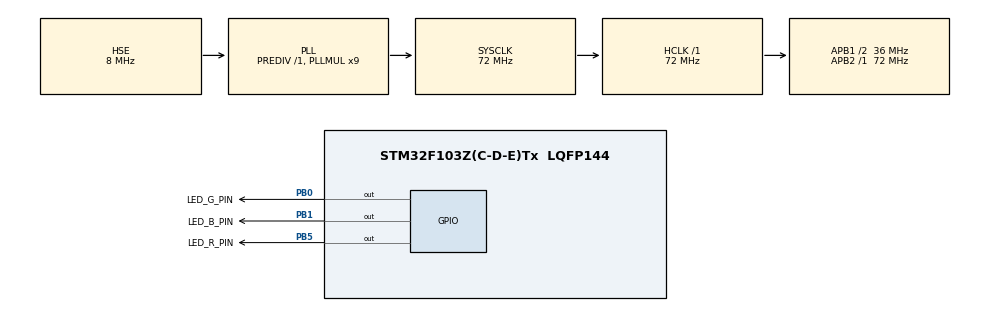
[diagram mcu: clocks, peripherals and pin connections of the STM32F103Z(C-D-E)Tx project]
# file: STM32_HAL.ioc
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Mcu.Family=STM32F1
Mcu.Name=STM32F103Z(C-D-E)Tx
Mcu.Package=LQFP144
NVIC.PriorityGroup=NVIC_PRIORITYGROUP_4
OSC_IN.Mode=HSE-External-Oscillator
OSC_IN.Signal=RCC_OSC_IN
OSC_OUT.Mode=HSE-External-Oscillator
OSC_OUT.Signal=RCC_OSC_OUT
PA13.Mode=JTAG_5_pins
PA13.Signal=SYS_JTMS-SWDIO
PA14.Mode=JTAG_5_pins
PA14.Signal=SYS_JTCK-SWCLK
PA15.Mode=JTAG_5_pins
PA15.Signal=SYS_JTDI
PB0.GPIO_Label=LED_G_PIN
PB0.GPIO_Speed=GPIO_SPEED_FREQ_HIGH
PB0.PinState=GPIO_PIN_SET
PB0.Signal=GPIO_Output
PB1.GPIO_Label=LED_B_PIN
PB1.GPIO_Speed=GPIO_SPEED_FREQ_HIGH
PB1.PinState=GPIO_PIN_SET
PB1.Signal=GPIO_Output
PB3.Mode=JTAG_5_pins
PB3.Signal=SYS_JTDO-TRACESWO
PB4.Mode=JTAG_5_pins
PB4.Signal=SYS_NJTRST
PB5.GPIO_Label=LED_R_PIN
PB5.GPIO_Speed=GPIO_SPEED_FREQ_HIGH
PB5.PinState=GPIO_PIN_SET
PB5.Signal=GPIO_Output
PC14-OSC32_IN.Mode=LSE-External-Oscillator
PC14-OSC32_IN.Signal=RCC_OSC32_IN
PC15-OSC32_OUT.Mode=LSE-External-Oscillator
PC15-OSC32_OUT.Signal=RCC_OSC32_OUT
ProjectManager.HeapSize=0x200
ProjectManager.StackSize=0x400
ProjectManager.TargetToolchain=CMake
RCC.AHBFreq_Value=72000000
RCC.APB1CLKDivider=RCC_HCLK_DIV2
RCC.APB1Freq_Value=36000000
RCC.APB1TimFreq_Value=72000000
RCC.APB2Freq_Value=72000000
RCC.APB2TimFreq_Value=72000000
RCC.HCLKFreq_Value=72000000
RCC.PLLMUL=RCC_PLL_MUL9
RCC.PLLSourceVirtual=RCC_PLLSOURCE_HSE
RCC.SYSCLKFreq_VALUE=72000000
RCC.SYSCLKSource=RCC_SYSCLKSOURCE_PLLCLK
RCC.USBFreq_Value=72000000
board=custom

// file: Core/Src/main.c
/* USER CODE BEGIN Header */
/**
  ******************************************************************************
  * @file           : main.c
  * @brief          : Main program body
  ******************************************************************************
  * @attention
  *
  * Copyright (c) 2024 STMicroelectronics.
  * All rights reserved.
  *
  * This software is licensed under terms that can be found in the LICENSE file
  * in the root directory of this software component.
  * If no LICENSE file comes with this software, it is provided AS-IS.
  *
  ******************************************************************************
  */
/* USER CODE END Header */
#include "main.h"
#include "gpio.h"

/* USER CODE BEGIN PM */

// R: PB5, G: PB0, B: PB1
// #define LED_G 0b111111111111111111111111 11111110
// #define LED_B 0b111111111111111111111111 11111101
// #define LED_R 0b111111111111111111111111 11011111

#define LED_R 0xFFFFFFDF
#define LED_G 0xFFFFFFFE
#define LED_B 0xFFFFFFFD

/* USER CODE END PM */

void SystemClock_Config(void);

int main(void)
{

  /* MCU Configuration--------------------------------------------------------*/

  /* Reset of all peripherals, Initializes the Flash interface and the Systick. */
  HAL_Init();

  /* Configure the system clock */
  SystemClock_Config();

  /* Initialize all configured peripherals */
  MX_GPIO_Init();

  /* Infinite loop */
  /* USER CODE BEGIN WHILE */
  __HAL_RCC_GPIOF_CLK_ENABLE();

  GPIO_InitTypeDef ledGpio;
  ledGpio.Mode = GPIO_MODE_OUTPUT_OD;
  ledGpio.Pin = GPIO_PIN_6 | GPIO_PIN_7;
  ledGpio.Pull = GPIO_NOPULL;
  ledGpio.Speed = GPIO_SPEED_FREQ_HIGH;
  HAL_GPIO_Init(GPIOF, &ledGpio);

  while (1)
  {
    /* USER CODE END WHILE */

    /* USER CODE BEGIN 3 */

    HAL_GPIO_TogglePin(GPIOF, GPIO_PIN_6);
    HAL_Delay(100);
    HAL_GPIO_TogglePin(GPIOF, GPIO_PIN_7);
    HAL_Delay(100);

    // GPIOB->ODR = LED_R;
    // HAL_Delay(500);
    // GPIOB->ODR = LED_G;
    // HAL_Delay(500);
    // GPIOB->ODR = LED_B;
    // HAL_Delay(500);
  }
  /* USER CODE END 3 */
}

void SystemClock_Config(void)
{
  RCC_OscInitTypeDef RCC_OscInitStruct = {0};
  RCC_ClkInitTypeDef RCC_ClkInitStruct = {0};

  /** Initializes the RCC Oscillators according to the specified parameters
  * in the RCC_OscInitTypeDef structure.
  */
  RCC_OscInitStruct.OscillatorType = RCC_OSCILLATORTYPE_HSE;
  RCC_OscInitStruct.HSEState = RCC_HSE_ON;
  RCC_OscInitStruct.HSEPredivValue = RCC_HSE_PREDIV_DIV1;
  RCC_OscInitStruct.HSIState = RCC_HSI_ON;
  RCC_OscInitStruct.PLL.PLLState = RCC_PLL_ON;
  RCC_OscInitStruct.PLL.PLLSource = RCC_PLLSOURCE_HSE;
  RCC_OscInitStruct.PLL.PLLMUL = RCC_PLL_MUL9;
  if (HAL_RCC_OscConfig(&RCC_OscInitStruct) != HAL_OK)
  {
    Error_Handler();
  }

  /** Initializes the CPU, AHB and APB buses clocks
  */
  RCC_ClkInitStruct.ClockType = RCC_CLOCKTYPE_HCLK|RCC_CLOCKTYPE_SYSCLK
                              |RCC_CLOCKTYPE_PCLK1|RCC_CLOCKTYPE_PCLK2;
  RCC_ClkInitStruct.SYSCLKSource = RCC_SYSCLKSOURCE_PLLCLK;
  RCC_ClkInitStruct.AHBCLKDivider = RCC_SYSCLK_DIV1;
  RCC_ClkInitStruct.APB1CLKDivider = RCC_HCLK_DIV2;
  RCC_ClkInitStruct.APB2CLKDivider = RCC_HCLK_DIV1;

  if (HAL_RCC_ClockConfig(&RCC_ClkInitStruct, FLASH_LATENCY_2) != HAL_OK)
  {
    Error_Handler();
  }
}

void Error_Handler(void)
{
  __disable_irq();
  while (1)
  {
  }
}
